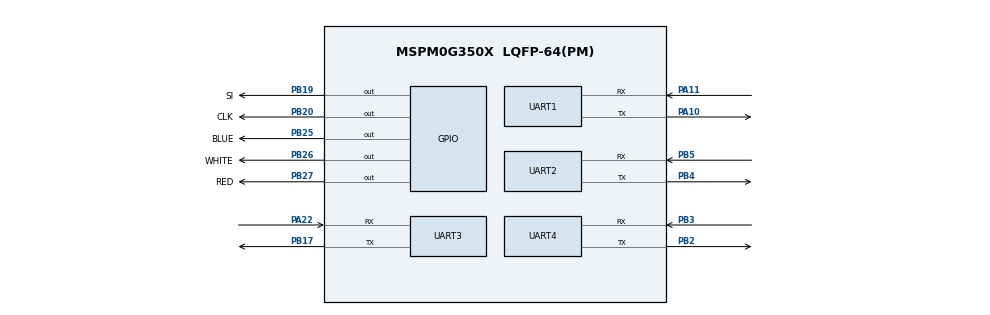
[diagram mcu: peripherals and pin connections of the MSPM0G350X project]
/**
 * @cliArgs --device "MSPM0G350X" --part "Default" --package "LQFP-64(PM)" --product "mspm0_sdk@2.11.00.07"
 * @versions {"tool":"1.26.2+4477"}
 */

/**
 * Import the modules used in this configuration.
 */
const SYSCTL = scripting.addModule("/ti/driverlib/SYSCTL");
const UART   = scripting.addModule("/ti/driverlib/UART", {}, false);
const UART1  = UART.addInstance();
const UART2  = UART.addInstance();
const UART3  = UART.addInstance();
const UART4  = UART.addInstance();
const WWDT   = scripting.addModule("/ti/driverlib/WWDT", {}, false);
const WWDT1  = WWDT.addInstance();

/**
 * Write custom configuration values to the imported modules.
 */

const Board = scripting.addModule("/ti/driverlib/Board", {}, false);

SYSCTL.forceDefaultClkConfig = true;
SYSCTL.clockTreeEn           = true;

UART1.$name                            = "DEBUG_UART";
UART1.targetBaudRate                   = 115200;
UART1.enableFIFO                       = true;
UART1.enabledInterrupts                = ["RX"];
UART1.peripheral.$assign               = "UART0";
UART1.peripheral.rxPin.$assign         = "PA11";
UART1.peripheral.txPin.$assign         = "PA10";
UART1.txPinConfig.$name                = "ti_driverlib_gpio_GPIOPinGeneric0";
UART1.txPinConfig.direction            = scripting.forceWrite("OUTPUT");
UART1.txPinConfig.hideOutputInversion  = scripting.forceWrite(false);
UART1.txPinConfig.onlyInternalResistor = scripting.forceWrite(false);
UART1.txPinConfig.passedPeripheralType = scripting.forceWrite("Digital");
UART1.rxPinConfig.$name                = "ti_driverlib_gpio_GPIOPinGeneric1";
UART1.rxPinConfig.hideOutputInversion  = scripting.forceWrite(false);
UART1.rxPinConfig.onlyInternalResistor = scripting.forceWrite(false);
UART1.rxPinConfig.passedPeripheralType = scripting.forceWrite("Digital");

UART2.$name                            = "DRIVE_UART";
UART2.targetBaudRate                   = 115200;
UART2.enableFIFO                       = true;
UART2.enabledInterrupts                = ["RX"];
UART2.peripheral.$assign               = "UART1";
UART2.peripheral.rxPin.$assign         = "PB5";
UART2.peripheral.txPin.$assign         = "PB4";
UART2.txPinConfig.$name                = "ti_driverlib_gpio_GPIOPinGeneric2";
UART2.txPinConfig.direction            = scripting.forceWrite("OUTPUT");
UART2.txPinConfig.hideOutputInversion  = scripting.forceWrite(false);
UART2.txPinConfig.onlyInternalResistor = scripting.forceWrite(false);
UART2.txPinConfig.passedPeripheralType = scripting.forceWrite("Digital");
UART2.rxPinConfig.$name                = "ti_driverlib_gpio_GPIOPinGeneric3";
UART2.rxPinConfig.hideOutputInversion  = scripting.forceWrite(false);
UART2.rxPinConfig.onlyInternalResistor = scripting.forceWrite(false);
UART2.rxPinConfig.passedPeripheralType = scripting.forceWrite("Digital");

UART3.$name                            = "IMU_UART";
UART3.targetBaudRate                   = 115200;
UART3.enableFIFO                       = true;
UART3.enabledInterrupts                = ["RX"];
UART3.peripheral.$assign               = "UART2";
UART3.peripheral.rxPin.$assign         = "PA22";
UART3.peripheral.txPin.$assign         = "PB17";
UART3.txPinConfig.$name                = "ti_driverlib_gpio_GPIOPinGeneric4";
UART3.txPinConfig.direction            = scripting.forceWrite("OUTPUT");
UART3.txPinConfig.hideOutputInversion  = scripting.forceWrite(false);
UART3.txPinConfig.onlyInternalResistor = scripting.forceWrite(false);
UART3.txPinConfig.passedPeripheralType = scripting.forceWrite("Digital");
UART3.rxPinConfig.$name                = "ti_driverlib_gpio_GPIOPinGeneric5";
UART3.rxPinConfig.hideOutputInversion  = scripting.forceWrite(false);
UART3.rxPinConfig.onlyInternalResistor = scripting.forceWrite(false);
UART3.rxPinConfig.passedPeripheralType = scripting.forceWrite("Digital");

UART4.$name                            = "K230_UART";
UART4.targetBaudRate                   = 115200;
UART4.enableFIFO                       = true;
UART4.enabledInterrupts                = ["RX"];
UART4.peripheral.$assign               = "UART3";
UART4.peripheral.rxPin.$assign         = "PB3";
UART4.peripheral.txPin.$assign         = "PB2";
UART4.txPinConfig.$name                = "ti_driverlib_gpio_GPIOPinGeneric6";
UART4.txPinConfig.direction            = scripting.forceWrite("OUTPUT");
UART4.txPinConfig.hideOutputInversion  = scripting.forceWrite(false);
UART4.txPinConfig.onlyInternalResistor = scripting.forceWrite(false);
UART4.txPinConfig.passedPeripheralType = scripting.forceWrite("Digital");
UART4.rxPinConfig.$name                = "ti_driverlib_gpio_GPIOPinGeneric7";
UART4.rxPinConfig.hideOutputInversion  = scripting.forceWrite(false);
UART4.rxPinConfig.onlyInternalResistor = scripting.forceWrite(false);
UART4.rxPinConfig.passedPeripheralType = scripting.forceWrite("Digital");

/* ==== 主循环看门狗: 8s 周期, 0% 关闭窗口, 只在 main loop 末尾喂狗 ==== */
WWDT1.$name                = "WWDT0";
WWDT1.clockDivider         = "8";
WWDT1.periodCount          = "15";
WWDT1.window0ClosedPeriod  = "0";
WWDT1.sleepMode            = true;
WWDT1.peripheral.$assign   = "WWDT0";

/* ==== 线性CCD TSL1401 (WHEELTEC) ==== */
/* AO(模拟输出)  -> PB18 = ADC1 通道5 (adcPin5)                         */
/* SI(启动脉冲)   -> PB19  GPIO 输出                                     */
/* CLK(移位时钟)  -> PB20  GPIO 输出                                     */
const ADC12  = scripting.addModule("/ti/driverlib/ADC12", {}, false);
const ADC121 = ADC12.addInstance();
const GPIO   = scripting.addModule("/ti/driverlib/GPIO", {}, false);
const GPIO1  = GPIO.addInstance();
const GPIO2  = GPIO.addInstance();

ADC121.$name                      = "CCD_ADC";
ADC121.sampClkSrc                 = "DL_ADC12_CLOCK_ULPCLK";
ADC121.sampClkDiv                 = "DL_ADC12_CLOCK_DIVIDE_8";
ADC121.adcMem0chansel             = "DL_ADC12_INPUT_CHAN_5";   // PB18 = A5
ADC121.sampleTime0                = "4 us";
ADC121.powerDownMode              = "DL_ADC12_POWER_DOWN_MODE_MANUAL";
ADC121.peripheral.$assign         = "ADC1";
ADC121.peripheral.adcPin5.$assign = "PB18";

GPIO1.$name                                 = "CCD_IO";
GPIO1.associatedPins.create(2);
GPIO1.associatedPins[0].$name               = "SI";
GPIO1.associatedPins[0].assignedPort        = "PORTB";
GPIO1.associatedPins[0].assignedPortSegment = "Upper";
GPIO1.associatedPins[0].assignedPin         = "19";
GPIO1.associatedPins[0].initialValue        = "CLEARED";
GPIO1.associatedPins[0].pin.$assign         = "PB19";
GPIO1.associatedPins[1].$name               = "CLK";
GPIO1.associatedPins[1].assignedPort        = "PORTB";
GPIO1.associatedPins[1].assignedPortSegment = "Upper";
GPIO1.associatedPins[1].assignedPin         = "20";
GPIO1.associatedPins[1].initialValue        = "SET";
GPIO1.associatedPins[1].pin.$assign         = "PB20";

/* ==== 三色 LED (共阳/VCC=3.3V, GPIO 低=亮) ==== */
/* 蓝->PB25  白->PB26  红->PB27, 初始高电平=灭                        */
GPIO2.$name                                 = "LED3";
GPIO2.associatedPins.create(3);
GPIO2.associatedPins[0].$name               = "BLUE";
GPIO2.associatedPins[0].assignedPort        = "PORTB";
GPIO2.associatedPins[0].assignedPortSegment = "Upper";
GPIO2.associatedPins[0].assignedPin         = "25";
GPIO2.associatedPins[0].initialValue        = "SET";
GPIO2.associatedPins[0].pin.$assign         = "PB25";
GPIO2.associatedPins[1].$name               = "WHITE";
GPIO2.associatedPins[1].assignedPort        = "PORTB";
GPIO2.associatedPins[1].assignedPortSegment = "Upper";
GPIO2.associatedPins[1].assignedPin         = "26";
GPIO2.associatedPins[1].initialValue        = "SET";
GPIO2.associatedPins[1].pin.$assign         = "PB26";
GPIO2.associatedPins[2].$name               = "RED";
GPIO2.associatedPins[2].assignedPort        = "PORTB";
GPIO2.associatedPins[2].assignedPortSegment = "Upper";
GPIO2.associatedPins[2].assignedPin         = "27";
GPIO2.associatedPins[2].initialValue        = "SET";
GPIO2.associatedPins[2].pin.$assign         = "PB27";

/**
 * Pinmux solution for unlocked pins/peripherals. This ensures that minor changes to the automatic solver in a future
 * version of the tool will not impact the pinmux you originally saw.  These lines can be completely deleted in order to
 * re-solve from scratch.
 */
Board.peripheral.$suggestSolution          = "DEBUGSS";
Board.peripheral.swclkPin.$suggestSolution = "PA20";
Board.peripheral.swdioPin.$suggestSolution = "PA19";
